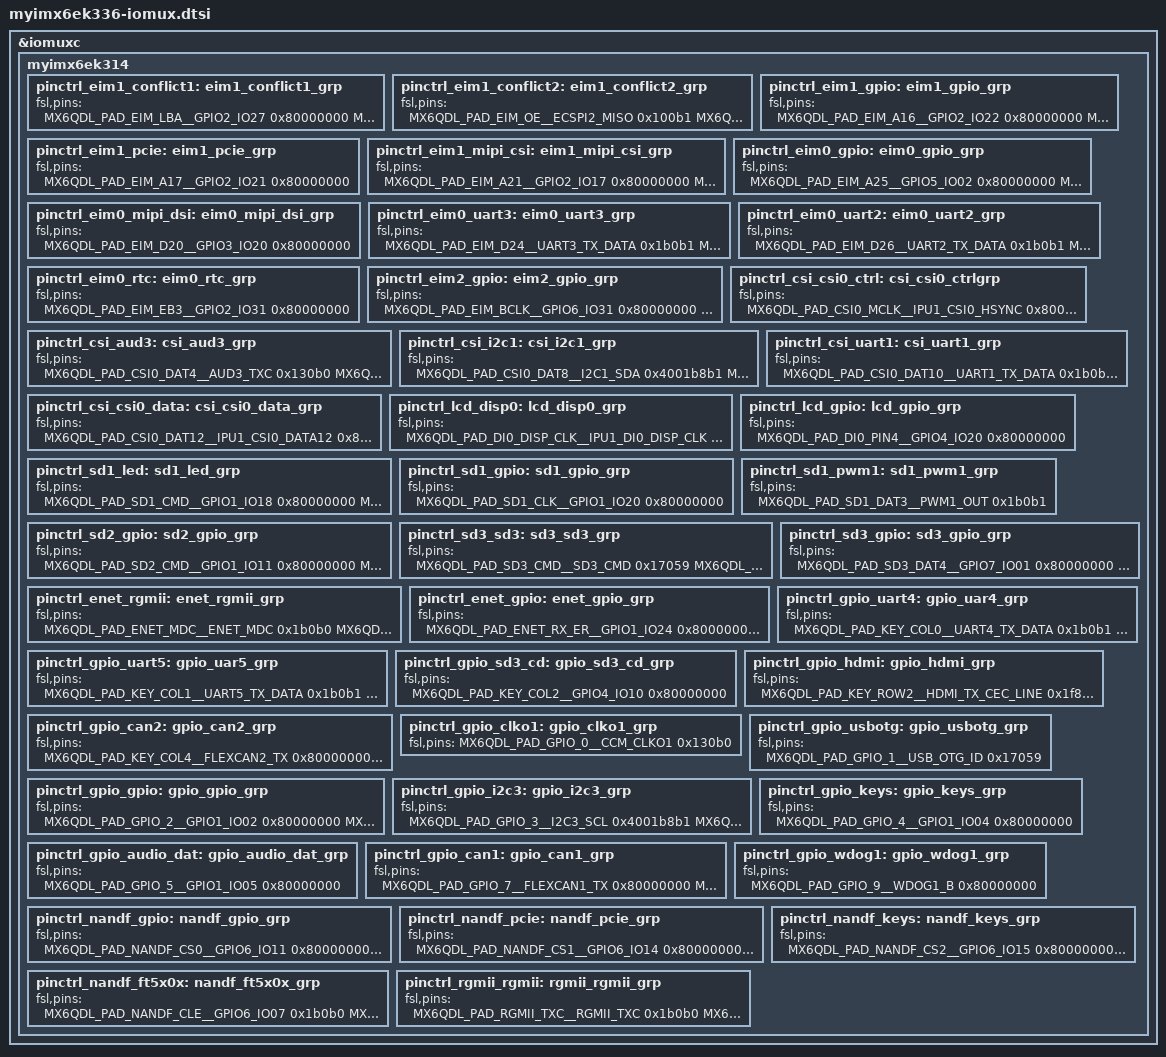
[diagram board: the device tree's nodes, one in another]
/*
 * MYZR Technology Co.,Ltd
 * http://www.myzr.com.cn
 * Tang Bin <tangb@myzr.com.cn>
 */

&iomuxc {
	myimx6ek314 {
		pinctrl_eim1_conflict1: eim1_conflict1_grp {
			fsl,pins = <	/* SPI2 or EIM */
				MX6QDL_PAD_EIM_LBA__GPIO2_IO27		0x80000000
				MX6QDL_PAD_EIM_RW__GPIO2_IO26		0x80000000
			>;
		};
		pinctrl_eim1_conflict2: eim1_conflict2_grp {
			fsl,pins = <	/* SPI2 or EIM */
				MX6QDL_PAD_EIM_OE__ECSPI2_MISO 		0x100b1
				MX6QDL_PAD_EIM_CS0__ECSPI2_SCLK 	0x100b1
				MX6QDL_PAD_EIM_CS1__ECSPI2_MOSI 	0x100b1
			>;
		};
		pinctrl_eim1_gpio: eim1_gpio_grp {
			fsl,pins = <	/* EK314, NC */
				MX6QDL_PAD_EIM_A16__GPIO2_IO22		0x80000000
				MX6QDL_PAD_EIM_A18__GPIO2_IO20		0x80000000
				MX6QDL_PAD_EIM_A19__GPIO2_IO19		0x80000000
				MX6QDL_PAD_EIM_A20__GPIO2_IO18		0x80000000
				MX6QDL_PAD_EIM_A23__GPIO6_IO06		0x80000000
				MX6QDL_PAD_EIM_A24__GPIO5_IO04		0x80000000
			>;
		};
		pinctrl_eim1_pcie: eim1_pcie_grp {
			fsl,pins = <
				MX6QDL_PAD_EIM_A17__GPIO2_IO21		0x80000000	/* PCIE, WAKE */
			>;
		};
		pinctrl_eim1_mipi_csi: eim1_mipi_csi_grp {
			fsl,pins = <	/* MIPI CSI IO */
				MX6QDL_PAD_EIM_A21__GPIO2_IO17		0x80000000
				MX6QDL_PAD_EIM_A22__GPIO2_IO16		0x80000000
			>;
		};
		
		pinctrl_eim0_gpio: eim0_gpio_grp {
			fsl,pins = <
				MX6QDL_PAD_EIM_A25__GPIO5_IO02		0x80000000	/* J13:5 */
				MX6QDL_PAD_EIM_D21__GPIO3_IO21		0x80000000	/* U14:29 */
				MX6QDL_PAD_EIM_D22__GPIO3_IO22		0x80000000	/* U14:30 */
				MX6QDL_PAD_EIM_D23__GPIO3_IO23		0x80000000	/* J12:14 */
				MX6QDL_PAD_EIM_D28__GPIO3_IO28		0x80000000	/* J12:7 */
				MX6QDL_PAD_EIM_D29__GPIO3_IO29		0x80000000	/* J12:8 */
				MX6QDL_PAD_EIM_D30__GPIO3_IO30		0x80000000	/* J23:12 */
				MX6QDL_PAD_EIM_D31__GPIO3_IO31		0x80000000	/* J12:11 */
			>;
		};
		pinctrl_eim0_mipi_dsi: eim0_mipi_dsi_grp {
			fsl,pins = <
				MX6QDL_PAD_EIM_D20__GPIO3_IO20		0x80000000	/* MIPI DSI, RST */
			>;
		};
		pinctrl_eim0_uart3: eim0_uart3_grp {
			fsl,pins = <	/* TTL(J12:31,12) and RS485 */
				MX6QDL_PAD_EIM_D24__UART3_TX_DATA	0x1b0b1
				MX6QDL_PAD_EIM_D25__UART3_RX_DATA	0x1b0b1
			>;
		};
		
		pinctrl_eim0_uart2: eim0_uart2_grp {
			fsl,pins = <	/* TTL(J12:10,9) */
				MX6QDL_PAD_EIM_D26__UART2_TX_DATA	0x1b0b1
				MX6QDL_PAD_EIM_D27__UART2_RX_DATA	0x1b0b1
			>;
		};
		pinctrl_eim0_rtc: eim0_rtc_grp {
			fsl,pins = <
				MX6QDL_PAD_EIM_EB3__GPIO2_IO31		0x80000000	/* RTC, nRQ */
			>;
		};
		
		pinctrl_eim2_gpio: eim2_gpio_grp {
			fsl,pins = <	/* EIM Pad */
				MX6QDL_PAD_EIM_BCLK__GPIO6_IO31		0x80000000
				MX6QDL_PAD_EIM_WAIT__GPIO5_IO00		0x80000000
				MX6QDL_PAD_EIM_EB0__GPIO2_IO28		0x80000000
				MX6QDL_PAD_EIM_EB1__GPIO2_IO29		0x80000000
				MX6QDL_PAD_EIM_DA0__GPIO3_IO00		0x80000000
				MX6QDL_PAD_EIM_DA1__GPIO3_IO01		0x80000000
				MX6QDL_PAD_EIM_DA2__GPIO3_IO02		0x80000000
				MX6QDL_PAD_EIM_DA3__GPIO3_IO03		0x80000000
				MX6QDL_PAD_EIM_DA4__GPIO3_IO04		0x80000000
				MX6QDL_PAD_EIM_DA5__GPIO3_IO05		0x80000000
				MX6QDL_PAD_EIM_DA6__GPIO3_IO06		0x80000000
				MX6QDL_PAD_EIM_DA7__GPIO3_IO07		0x80000000
				MX6QDL_PAD_EIM_DA8__GPIO3_IO08		0x80000000
				MX6QDL_PAD_EIM_DA9__GPIO3_IO09		0x80000000
				MX6QDL_PAD_EIM_DA10__GPIO3_IO10		0x80000000
				MX6QDL_PAD_EIM_DA11__GPIO3_IO11		0x80000000
				MX6QDL_PAD_EIM_DA12__GPIO3_IO12		0x80000000
				MX6QDL_PAD_EIM_DA13__GPIO3_IO13		0x80000000
				MX6QDL_PAD_EIM_DA14__GPIO3_IO14		0x80000000
				MX6QDL_PAD_EIM_DA15__GPIO3_IO15		0x80000000
			>;
		};
		
		pinctrl_csi_csi0_ctrl: csi_csi0_ctrlgrp {
			fsl,pins = <	/* OV5642 */
				MX6QDL_PAD_CSI0_MCLK__IPU1_CSI0_HSYNC		0x80000000
				MX6QDL_PAD_CSI0_PIXCLK__IPU1_CSI0_PIXCLK	0x80000000
				MX6QDL_PAD_CSI0_VSYNC__IPU1_CSI0_VSYNC		0x80000000
				MX6QDL_PAD_CSI0_DATA_EN__GPIO5_IO20			0x80000000
			>;
		};
		pinctrl_csi_aud3: csi_aud3_grp {
			fsl,pins = <	/* WM8962 */
				MX6QDL_PAD_CSI0_DAT4__AUD3_TXC				0x130b0
				MX6QDL_PAD_CSI0_DAT5__AUD3_TXD				0x110b0
				MX6QDL_PAD_CSI0_DAT6__AUD3_TXFS				0x130b0
				MX6QDL_PAD_CSI0_DAT7__AUD3_RXD				0x130b0
			>;
		};
		pinctrl_csi_i2c1: csi_i2c1_grp {
			fsl,pins = <	/* I2C1 */
				MX6QDL_PAD_CSI0_DAT8__I2C1_SDA				0x4001b8b1
				MX6QDL_PAD_CSI0_DAT9__I2C1_SCL				0x4001b8b1
			>;
		};
		pinctrl_csi_uart1: csi_uart1_grp {
			fsl,pins = <	/* Debug UART */
				MX6QDL_PAD_CSI0_DAT10__UART1_TX_DATA		0x1b0b1
				MX6QDL_PAD_CSI0_DAT11__UART1_RX_DATA		0x1b0b1
			>;
		};
		pinctrl_csi_csi0_data: csi_csi0_data_grp {
			fsl,pins = <	/* OV5642 */
				MX6QDL_PAD_CSI0_DAT12__IPU1_CSI0_DATA12		0x80000000
				MX6QDL_PAD_CSI0_DAT13__IPU1_CSI0_DATA13		0x80000000
				MX6QDL_PAD_CSI0_DAT14__IPU1_CSI0_DATA14		0x80000000
				MX6QDL_PAD_CSI0_DAT15__IPU1_CSI0_DATA15		0x80000000
				MX6QDL_PAD_CSI0_DAT16__IPU1_CSI0_DATA16		0x80000000
				MX6QDL_PAD_CSI0_DAT17__IPU1_CSI0_DATA17		0x80000000
				MX6QDL_PAD_CSI0_DAT18__IPU1_CSI0_DATA18		0x80000000
				MX6QDL_PAD_CSI0_DAT19__IPU1_CSI0_DATA19		0x80000000
			>;
		};
		
		pinctrl_lcd_disp0: lcd_disp0_grp {
			fsl,pins = <	/* LCD(RGB) */
				MX6QDL_PAD_DI0_DISP_CLK__IPU1_DI0_DISP_CLK 0x10
				MX6QDL_PAD_DI0_PIN2__IPU1_DI0_PIN02        0x10
				MX6QDL_PAD_DI0_PIN3__IPU1_DI0_PIN03        0x10
				MX6QDL_PAD_DI0_PIN15__IPU1_DI0_PIN15       0x10
				MX6QDL_PAD_DISP0_DAT0__IPU1_DISP0_DATA00   0x10
				MX6QDL_PAD_DISP0_DAT1__IPU1_DISP0_DATA01   0x10
				MX6QDL_PAD_DISP0_DAT2__IPU1_DISP0_DATA02   0x10
				MX6QDL_PAD_DISP0_DAT3__IPU1_DISP0_DATA03   0x10
				MX6QDL_PAD_DISP0_DAT4__IPU1_DISP0_DATA04   0x10
				MX6QDL_PAD_DISP0_DAT5__IPU1_DISP0_DATA05   0x10
				MX6QDL_PAD_DISP0_DAT6__IPU1_DISP0_DATA06   0x10
				MX6QDL_PAD_DISP0_DAT7__IPU1_DISP0_DATA07   0x10
				MX6QDL_PAD_DISP0_DAT8__IPU1_DISP0_DATA08   0x10
				MX6QDL_PAD_DISP0_DAT9__IPU1_DISP0_DATA09   0x10
				MX6QDL_PAD_DISP0_DAT10__IPU1_DISP0_DATA10  0x10
				MX6QDL_PAD_DISP0_DAT11__IPU1_DISP0_DATA11  0x10
				MX6QDL_PAD_DISP0_DAT12__IPU1_DISP0_DATA12  0x10
				MX6QDL_PAD_DISP0_DAT13__IPU1_DISP0_DATA13  0x10
				MX6QDL_PAD_DISP0_DAT14__IPU1_DISP0_DATA14  0x10
				MX6QDL_PAD_DISP0_DAT15__IPU1_DISP0_DATA15  0x10
				MX6QDL_PAD_DISP0_DAT16__IPU1_DISP0_DATA16  0x10
				MX6QDL_PAD_DISP0_DAT17__IPU1_DISP0_DATA17  0x10
				MX6QDL_PAD_DISP0_DAT18__IPU1_DISP0_DATA18  0x10
				MX6QDL_PAD_DISP0_DAT19__IPU1_DISP0_DATA19  0x10
				MX6QDL_PAD_DISP0_DAT20__IPU1_DISP0_DATA20  0x10
				MX6QDL_PAD_DISP0_DAT21__IPU1_DISP0_DATA21  0x10
				MX6QDL_PAD_DISP0_DAT22__IPU1_DISP0_DATA22  0x10
				MX6QDL_PAD_DISP0_DAT23__IPU1_DISP0_DATA23  0x10
			>;
		};
		pinctrl_lcd_gpio: lcd_gpio_grp {
			fsl,pins = <
				MX6QDL_PAD_DI0_PIN4__GPIO4_IO20			0x80000000	/* U14:37 */
			>;
		};
		
		pinctrl_sd1_led: sd1_led_grp {
			fsl,pins = <
				MX6QDL_PAD_SD1_CMD__GPIO1_IO18			0x80000000	/* LED4, D15 */
				MX6QDL_PAD_SD1_DAT0__GPIO1_IO16			0x80000000	/* LED1, D18 */
				MX6QDL_PAD_SD1_DAT1__GPIO1_IO17			0x80000000	/* LED2, D17 */
				MX6QDL_PAD_SD1_DAT2__GPIO1_IO19			0x80000000	/* LED3, D16 */
			>;
		};
		pinctrl_sd1_gpio: sd1_gpio_grp {
			fsl,pins = <
				MX6QDL_PAD_SD1_CLK__GPIO1_IO20			0x80000000	/* U14:35 */
			>;
		};
		pinctrl_sd1_pwm1: sd1_pwm1_grp {
			fsl,pins = <	/* BackLight and J24:6 */
				MX6QDL_PAD_SD1_DAT3__PWM1_OUT			0x1b0b1
			>;
		};
		
		pinctrl_sd2_gpio: sd2_gpio_grp {
			fsl,pins = <
				MX6QDL_PAD_SD2_CMD__GPIO1_IO11			0x80000000	/* U14:27 */
				MX6QDL_PAD_SD2_CLK__GPIO1_IO10			0x80000000	/* U14:23 */
				MX6QDL_PAD_SD2_DAT0__GPIO1_IO15			0x80000000	/* U14:24 */
				MX6QDL_PAD_SD2_DAT1__GPIO1_IO14			0x80000000	/* U14:28 */
				MX6QDL_PAD_SD2_DAT2__GPIO1_IO13			0x80000000	/* U14:26 */
				MX6QDL_PAD_SD2_DAT3__GPIO1_IO12			0x80000000	/* U14:25 */
			>;
		};
		
		pinctrl_sd3_sd3: sd3_sd3_grp {
			fsl,pins = <
				MX6QDL_PAD_SD3_CMD__SD3_CMD				0x17059
				MX6QDL_PAD_SD3_CLK__SD3_CLK				0x10059
				MX6QDL_PAD_SD3_DAT0__SD3_DATA0			0x17059
				MX6QDL_PAD_SD3_DAT1__SD3_DATA1			0x17059
				MX6QDL_PAD_SD3_DAT2__SD3_DATA2			0x17059
				MX6QDL_PAD_SD3_DAT3__SD3_DATA3			0x17059
				MX6QDL_PAD_SD3_RST__GPIO7_IO08			0x80000000	/* WP */
			>;
		};
		pinctrl_sd3_gpio: sd3_gpio_grp {
			fsl,pins = <
				MX6QDL_PAD_SD3_DAT4__GPIO7_IO01			0x80000000	/* U14:3 */
				MX6QDL_PAD_SD3_DAT5__GPIO7_IO00			0x80000000	/* U14:4 */
				MX6QDL_PAD_SD3_DAT6__GPIO6_IO18			0x80000000	/* U14:6 */
				MX6QDL_PAD_SD3_DAT7__GPIO6_IO17			0x80000000	/* U14:5 */
			>;
		};
		
		pinctrl_enet_rgmii: enet_rgmii_grp {
			fsl,pins = <
				MX6QDL_PAD_ENET_MDC__ENET_MDC			0x1b0b0
				MX6QDL_PAD_ENET_MDIO__ENET_MDIO			0x1b0b0
				MX6QDL_PAD_ENET_CRS_DV__GPIO1_IO25		0x80000000	/* RESET */
				MX6QDL_PAD_ENET_REF_CLK__ENET_TX_CLK	0x1b0b0		/* CLK125_MD0 */
				MX6QDL_PAD_ENET_TX_EN__GPIO1_IO28		0x000b1		/* INT */
			>;
		};
		pinctrl_enet_gpio: enet_gpio_grp {
			fsl,pins = <
				MX6QDL_PAD_ENET_RX_ER__GPIO1_IO24		0x80000000	/* U14:21 */
				MX6QDL_PAD_ENET_RXD0__GPIO1_IO27		0x80000000	/* U14:18 */
				MX6QDL_PAD_ENET_RXD1__GPIO1_IO26		0x80000000	/* U14:20 */
				MX6QDL_PAD_ENET_TXD0__GPIO1_IO30		0x80000000	/* U14:19 */
				MX6QDL_PAD_ENET_TXD1__GPIO1_IO29		0x80000000	/* U14:17 */
			>;
		};
		
		pinctrl_gpio_uart4: gpio_uar4_grp {
			fsl,pins = <	/* RS232(P2) and TTL(J12:15,17) */
				MX6QDL_PAD_KEY_COL0__UART4_TX_DATA		0x1b0b1
				MX6QDL_PAD_KEY_ROW0__UART4_RX_DATA		0x1b0b1
			>;
		};
		pinctrl_gpio_uart5: gpio_uar5_grp {
			fsl,pins = <	/* GPS(U27) and TTL(J12:16,18) */
				MX6QDL_PAD_KEY_COL1__UART5_TX_DATA		0x1b0b1
				MX6QDL_PAD_KEY_ROW1__UART5_RX_DATA		0x1b0b1
			>;
		};
		pinctrl_gpio_sd3_cd: gpio_sd3_cd_grp {
			fsl,pins = <
				MX6QDL_PAD_KEY_COL2__GPIO4_IO10 		0x80000000	/* SD3, CD */
			>;
		};
		pinctrl_gpio_hdmi: gpio_hdmi_grp {
			fsl,pins = <
				MX6QDL_PAD_KEY_ROW2__HDMI_TX_CEC_LINE	0x1f8b0
			>;
		};
		pinctrl_gpio_can2: gpio_can2_grp {
			fsl,pins = <	/* CAN2, J15 */
				MX6QDL_PAD_KEY_COL4__FLEXCAN2_TX	0x80000000
				MX6QDL_PAD_KEY_ROW4__FLEXCAN2_RX	0x80000000
			>;
		};
		pinctrl_gpio_clko1: gpio_clko1_grp {
			fsl,pins = <
				MX6QDL_PAD_GPIO_0__CCM_CLKO1		0x130b0
			>;
		};
		pinctrl_gpio_usbotg: gpio_usbotg_grp {
			fsl,pins = <
				MX6QDL_PAD_GPIO_1__USB_OTG_ID		0x17059
			>;
		};
		pinctrl_gpio_gpio: gpio_gpio_grp {
			fsl,pins = <
				MX6QDL_PAD_GPIO_2__GPIO1_IO02		0x80000000	/* J23:11 */
				MX6QDL_PAD_GPIO_19__GPIO4_IO05		0x80000000	/* J13:8 */
			>;
		};
		pinctrl_gpio_i2c3: gpio_i2c3_grp {
			fsl,pins = <	/* I2C3 */
				MX6QDL_PAD_GPIO_3__I2C3_SCL			0x4001b8b1
				MX6QDL_PAD_GPIO_6__I2C3_SDA			0x4001b8b1
			>;
		};
		pinctrl_gpio_keys: gpio_keys_grp {
			fsl,pins = <
				MX6QDL_PAD_GPIO_4__GPIO1_IO04  		0x80000000	/* KEY, WAKEUP */
			>;
		};
		pinctrl_gpio_audio_dat: gpio_audio_dat_grp {
			fsl,pins = <
				MX6QDL_PAD_GPIO_5__GPIO1_IO05  		0x80000000	/* WM8962 */
			>;
		};
		pinctrl_gpio_can1: gpio_can1_grp {
			fsl,pins = <	/* CAN1, J17 */
				MX6QDL_PAD_GPIO_7__FLEXCAN1_TX		0x80000000
				MX6QDL_PAD_GPIO_8__FLEXCAN1_RX		0x80000000
			>;
		};
		pinctrl_gpio_wdog1: gpio_wdog1_grp {
			fsl,pins = <	/* WDOG1_B */
				MX6QDL_PAD_GPIO_9__WDOG1_B			0x80000000
			>;
		};
		
		pinctrl_nandf_gpio: nandf_gpio_grp {
			fsl,pins = <
				MX6QDL_PAD_NANDF_CS0__GPIO6_IO11	0x80000000	/* U14:12 */
				MX6QDL_PAD_NANDF_CS3__GPIO6_IO16	0x80000000	/* U14:7 */
				MX6QDL_PAD_NANDF_WP_B__GPIO6_IO09	0x80000000	/* U14:11 */
				MX6QDL_PAD_NANDF_D0__GPIO2_IO00		0x80000000	/* U14:14 */
				MX6QDL_PAD_NANDF_D2__GPIO2_IO02		0x80000000	/* U14:13 */
				MX6QDL_PAD_NANDF_D3__GPIO2_IO03		0x80000000	/* U14:9 */
				MX6QDL_PAD_NANDF_D4__GPIO2_IO04		0x80000000	/* U14:15 */
				MX6QDL_PAD_NANDF_D5__GPIO2_IO05		0x80000000	/* U14:16 */
				MX6QDL_PAD_NANDF_D6__GPIO2_IO06		0x80000000	/* U14:10 */
				MX6QDL_PAD_NANDF_D7__GPIO2_IO07		0x80000000	/* U14:8 */
			>;
		};
		pinctrl_nandf_pcie: nandf_pcie_grp {
			fsl,pins = <
				MX6QDL_PAD_NANDF_CS1__GPIO6_IO14	0x80000000	/* PCIE, RERST */
				MX6QDL_PAD_NANDF_ALE__GPIO6_IO08	0x80000000	/* PCIE, W_DISABLE */
			>;
		};		
		pinctrl_nandf_keys: nandf_keys_grp {
			fsl,pins = <
				MX6QDL_PAD_NANDF_CS2__GPIO6_IO15	0x80000000	/* KEY, VOL+ */
				MX6QDL_PAD_NANDF_RB0__GPIO6_IO10	0x80000000	/* KEY, VOL- */
			>;
		};
		
		pinctrl_nandf_ft5x0x: nandf_ft5x0x_grp {
			fsl,pins = <
				MX6QDL_PAD_NANDF_CLE__GPIO6_IO07	0x1b0b0		/* TS: RST */
				MX6QDL_PAD_NANDF_D1__GPIO2_IO01		0x1b0b0		/* TS: INT */
			>;
		};
		
		pinctrl_rgmii_rgmii: rgmii_rgmii_grp {
			fsl,pins = <
				MX6QDL_PAD_RGMII_TXC__RGMII_TXC			0x1b0b0
				MX6QDL_PAD_RGMII_TD0__RGMII_TD0			0x1b0b0
				MX6QDL_PAD_RGMII_TD1__RGMII_TD1			0x1b0b0
				MX6QDL_PAD_RGMII_TD2__RGMII_TD2			0x1b0b0
				MX6QDL_PAD_RGMII_TD3__RGMII_TD3			0x1b0b0
				MX6QDL_PAD_RGMII_TX_CTL__RGMII_TX_CTL	0x1b0b0
				MX6QDL_PAD_RGMII_RXC__RGMII_RXC			0x1b0b0
				MX6QDL_PAD_RGMII_RD0__RGMII_RD0			0x1b0b0
				MX6QDL_PAD_RGMII_RD1__RGMII_RD1			0x1b0b0
				MX6QDL_PAD_RGMII_RD2__RGMII_RD2			0x1b0b0
				MX6QDL_PAD_RGMII_RD3__RGMII_RD3			0x1b0b0
				MX6QDL_PAD_RGMII_RX_CTL__RGMII_RX_CTL	0x1b0b0
			>;
		};
	};
};
